VERSION ""

NS_ :

BS_:

BU_: MASTER_BMS SUB_BMS
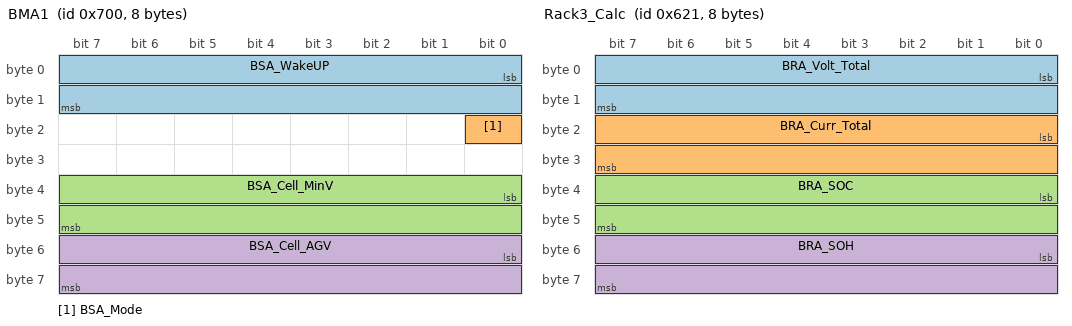
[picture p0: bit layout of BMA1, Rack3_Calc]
BO_ 1792 BMA1: 8 MASTER_BMS SUB_BMS
 SG_ BSA_WakeUP : 0|16@1+ (1.0,0) [0.0|1.0] "flag"  MASTER_BMS SUB_BMS
 SG_ BSA_Mode : 16|1@1+ (1.0,0) [0.0|1.0] "flag"  MASTER_BMS SUB_BMS
 SG_ BSA_Cell_MinV : 32|16@1+ (0.001,0) [2.8|4.5] "V"  MASTER_BMS SUB_BMS
 SG_ BSA_Cell_AGV : 48|16@1- (0.1,0) [-40.0|100.0] "℃"  MASTER_BMS SUB_BMS
BO_ 1569 Rack3_Calc: 8 MASTER_BMS SUB_BMS
 SG_ BRA_Volt_Total : 0|16@1+ (0.1,0) [40.0|120.0] "V"  MASTER_BMS SUB_BMS
 SG_ BRA_Curr_Total : 16|16@1- (0.1,0) [-500.0|500.0] "A"  MASTER_BMS SUB_BMS
 SG_ BRA_SOC : 32|16@1+ (0.1,0) [0.0|120.0] "%"  MASTER_BMS SUB_BMS
 SG_ BRA_SOH : 48|16@1- (0.1,0) [0.0|100.0] "%"  MASTER_BMS SUB_BMS
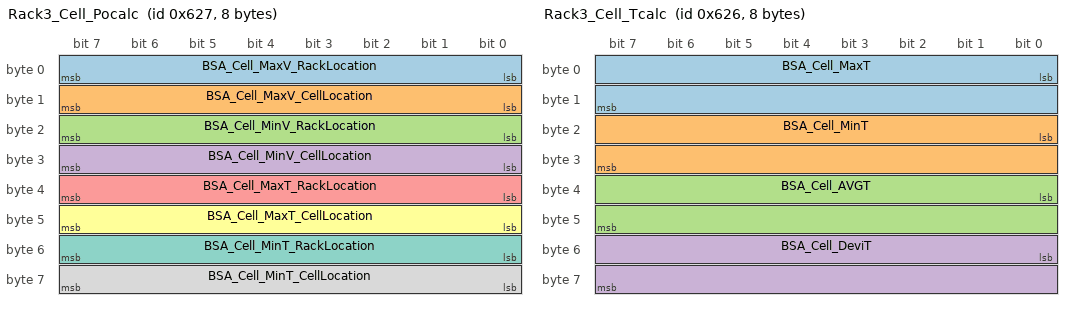
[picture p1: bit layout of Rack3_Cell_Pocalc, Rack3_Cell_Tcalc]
BO_ 1575 Rack3_Cell_Pocalc: 8 MASTER_BMS SUB_BMS
 SG_ BSA_Cell_MaxV_RackLocation : 0|8@1+ (1.0,0) [1.0|4.0] "R"  MASTER_BMS SUB_BMS
 SG_ BSA_Cell_MaxV_CellLocation : 8|8@1+ (1.0,0) [1.0|168.0] "C"  MASTER_BMS SUB_BMS
 SG_ BSA_Cell_MinV_RackLocation : 16|8@1+ (1.0,0) [1.0|4.0] "R"  MASTER_BMS SUB_BMS
 SG_ BSA_Cell_MinV_CellLocation : 24|8@1+ (1.0,0) [1.0|168.0] "C"  MASTER_BMS SUB_BMS
 SG_ BSA_Cell_MaxT_RackLocation : 32|8@1+ (1.0,0) [1.0|4.0] "R"  MASTER_BMS SUB_BMS
 SG_ BSA_Cell_MaxT_CellLocation : 40|8@1+ (1.0,0) [1.0|168.0] "C"  MASTER_BMS SUB_BMS
 SG_ BSA_Cell_MinT_RackLocation : 48|8@1+ (1.0,0) [1.0|4.0] "R"  MASTER_BMS SUB_BMS
 SG_ BSA_Cell_MinT_CellLocation : 56|8@1+ (1.0,0) [1.0|168.0] "C"  MASTER_BMS SUB_BMS
BO_ 1574 Rack3_Cell_Tcalc: 8 MASTER_BMS SUB_BMS
 SG_ BSA_Cell_MaxT : 0|16@1- (0.1,0) [-40.0|100.0] "℃"  MASTER_BMS SUB_BMS
 SG_ BSA_Cell_MinT : 16|16@1- (0.1,0) [-40.0|100.0] "℃"  MASTER_BMS SUB_BMS
 SG_ BSA_Cell_AVGT : 32|16@1- (0.1,0) [-40.0|100.0] "℃"  MASTER_BMS SUB_BMS
 SG_ BSA_Cell_DeviT : 48|16@1+ (0.1,0) [0.0|25.0] "℃"  MASTER_BMS SUB_BMS
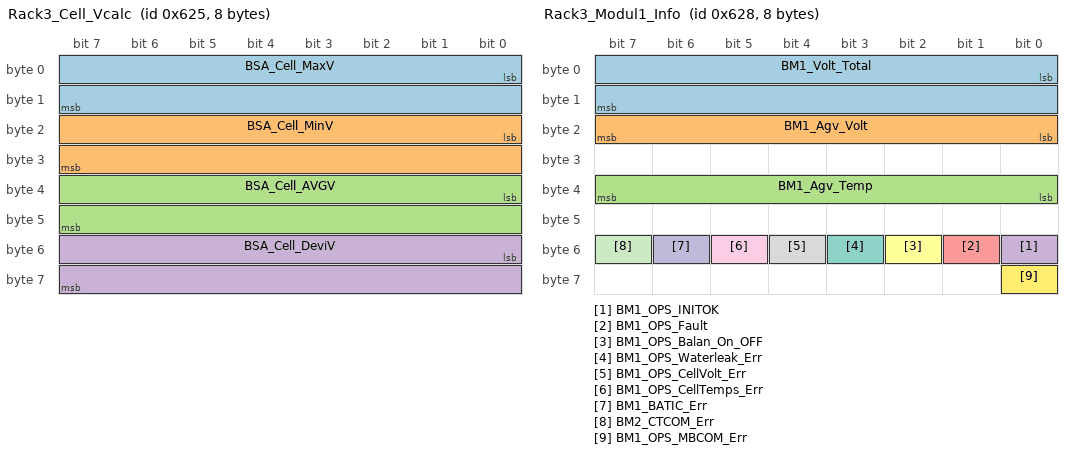
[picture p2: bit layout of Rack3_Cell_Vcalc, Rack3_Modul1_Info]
BO_ 1573 Rack3_Cell_Vcalc: 8 MASTER_BMS SUB_BMS
 SG_ BSA_Cell_MaxV : 0|16@1+ (0.001,0) [2.8|4.5] "V"  MASTER_BMS SUB_BMS
 SG_ BSA_Cell_MinV : 16|16@1+ (0.001,0) [2.8|4.5] "V"  MASTER_BMS SUB_BMS
 SG_ BSA_Cell_AVGV : 32|16@1+ (0.001,0) [2.8|4.5] "V"  MASTER_BMS SUB_BMS
 SG_ BSA_Cell_DeviV : 48|16@1+ (1.0,0) [0.0|500.0] "mV"  MASTER_BMS SUB_BMS
BO_ 1576 Rack3_Modul1_Info: 8 MASTER_BMS SUB_BMS
 SG_ BM1_Volt_Total : 0|16@1+ (0.1,0) [48.0|108.0] "V"  MASTER_BMS SUB_BMS
 SG_ BM1_Agv_Volt : 16|8@1+ (0.001,0) [2.8|4.5] "V"  MASTER_BMS SUB_BMS
 SG_ BM1_Agv_Temp : 32|8@1- (0.1,0) [-40.0|100.0] "℃"  MASTER_BMS SUB_BMS
 SG_ BM1_OPS_INITOK : 48|1@1+ (0.0,0) [0.0|1.0] "flag"  MASTER_BMS SUB_BMS
 SG_ BM1_OPS_Fault : 49|1@1+ (0.0,0) [0.0|1.0] "flag"  MASTER_BMS SUB_BMS
 SG_ BM1_OPS_Balan_On_OFF : 50|1@1+ (0.0,0) [0.0|1.0] "flag"  MASTER_BMS SUB_BMS
 SG_ BM1_OPS_Waterleak_Err : 51|1@1+ (0.0,0) [0.0|1.0] "flag"  MASTER_BMS SUB_BMS
 SG_ BM1_OPS_CellVolt_Err : 52|1@1+ (0.0,0) [0.0|1.0] "flag"  MASTER_BMS SUB_BMS
 SG_ BM1_OPS_CellTemps_Err : 53|1@1+ (0.0,0) [0.0|1.0] "flag"  MASTER_BMS SUB_BMS
 SG_ BM1_BATIC_Err : 54|1@1+ (0.0,0) [0.0|1.0] "flag"  MASTER_BMS SUB_BMS
 SG_ BM2_CTCOM_Err : 55|1@1+ (0.0,0) [0.0|1.0] "flag"  MASTER_BMS SUB_BMS
 SG_ BM1_OPS_MBCOM_Err : 56|1@1+ (0.0,0) [0.0|1.0] "flag"  MASTER_BMS SUB_BMS
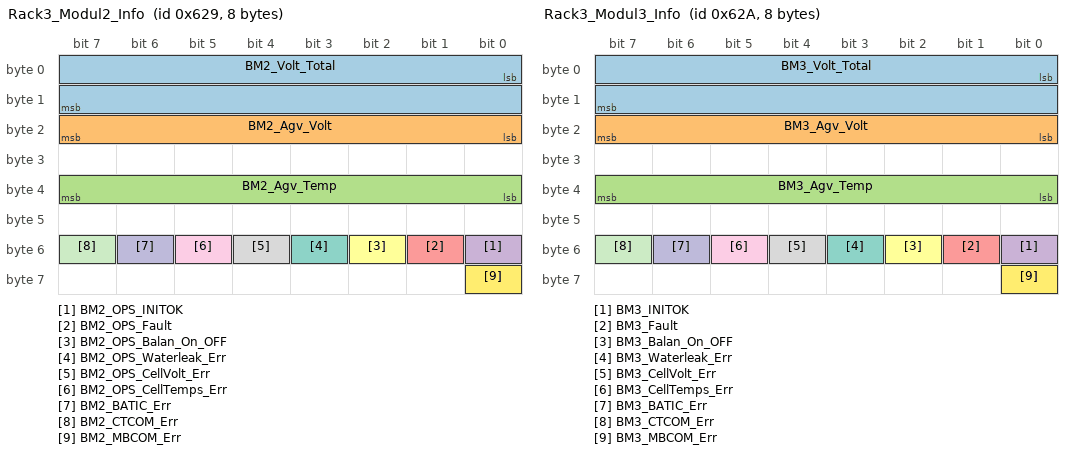
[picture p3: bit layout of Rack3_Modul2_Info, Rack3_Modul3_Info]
BO_ 1577 Rack3_Modul2_Info: 8 MASTER_BMS SUB_BMS
 SG_ BM2_Volt_Total : 0|16@1+ (0.1,0) [48.0|108.0] "V"  MASTER_BMS SUB_BMS
 SG_ BM2_Agv_Volt : 16|8@1+ (0.001,0) [2.8|4.5] "V"  MASTER_BMS SUB_BMS
 SG_ BM2_Agv_Temp : 32|8@1- (0.1,0) [-40.0|100.0] "℃"  MASTER_BMS SUB_BMS
 SG_ BM2_OPS_INITOK : 48|1@1+ (0.0,0) [0.0|1.0] "flag"  MASTER_BMS SUB_BMS
 SG_ BM2_OPS_Fault : 49|1@1+ (0.0,0) [0.0|1.0] "flag"  MASTER_BMS SUB_BMS
 SG_ BM2_OPS_Balan_On_OFF : 50|1@1+ (0.0,0) [0.0|1.0] "flag"  MASTER_BMS SUB_BMS
 SG_ BM2_OPS_Waterleak_Err : 51|1@1+ (0.0,0) [0.0|1.0] "flag"  MASTER_BMS SUB_BMS
 SG_ BM2_OPS_CellVolt_Err : 52|1@1+ (0.0,0) [0.0|1.0] "flag"  MASTER_BMS SUB_BMS
 SG_ BM2_OPS_CellTemps_Err : 53|1@1+ (0.0,0) [0.0|1.0] "flag"  MASTER_BMS SUB_BMS
 SG_ BM2_BATIC_Err : 54|1@1+ (0.0,0) [0.0|1.0] "flag"  MASTER_BMS SUB_BMS
 SG_ BM2_CTCOM_Err : 55|1@1+ (0.0,0) [0.0|1.0] "flag"  MASTER_BMS SUB_BMS
 SG_ BM2_MBCOM_Err : 56|1@1+ (0.0,0) [0.0|1.0] "flag"  MASTER_BMS SUB_BMS
BO_ 1578 Rack3_Modul3_Info: 8 MASTER_BMS SUB_BMS
 SG_ BM3_Volt_Total : 0|16@1+ (0.1,0) [48.0|108.0] "V"  MASTER_BMS SUB_BMS
 SG_ BM3_Agv_Volt : 16|8@1+ (0.001,0) [2.8|4.5] "V"  MASTER_BMS SUB_BMS
 SG_ BM3_Agv_Temp : 32|8@1- (0.1,0) [-40.0|100.0] "℃"  MASTER_BMS SUB_BMS
 SG_ BM3_INITOK : 48|1@1+ (0.0,0) [0.0|1.0] "flag"  MASTER_BMS SUB_BMS
 SG_ BM3_Fault : 49|1@1+ (0.0,0) [0.0|1.0] "flag"  MASTER_BMS SUB_BMS
 SG_ BM3_Balan_On_OFF : 50|1@1+ (0.0,0) [0.0|1.0] "flag"  MASTER_BMS SUB_BMS
 SG_ BM3_Waterleak_Err : 51|1@1+ (0.0,0) [0.0|1.0] "flag"  MASTER_BMS SUB_BMS
 SG_ BM3_CellVolt_Err : 52|1@1+ (0.0,0) [0.0|1.0] "flag"  MASTER_BMS SUB_BMS
 SG_ BM3_CellTemps_Err : 53|1@1+ (0.0,0) [0.0|1.0] "flag"  MASTER_BMS SUB_BMS
 SG_ BM3_BATIC_Err : 54|1@1+ (0.0,0) [0.0|1.0] "flag"  MASTER_BMS SUB_BMS
 SG_ BM3_CTCOM_Err : 55|1@1+ (0.0,0) [0.0|1.0] "flag"  MASTER_BMS SUB_BMS
 SG_ BM3_MBCOM_Err : 56|1@1+ (0.0,0) [0.0|1.0] "flag"  MASTER_BMS SUB_BMS
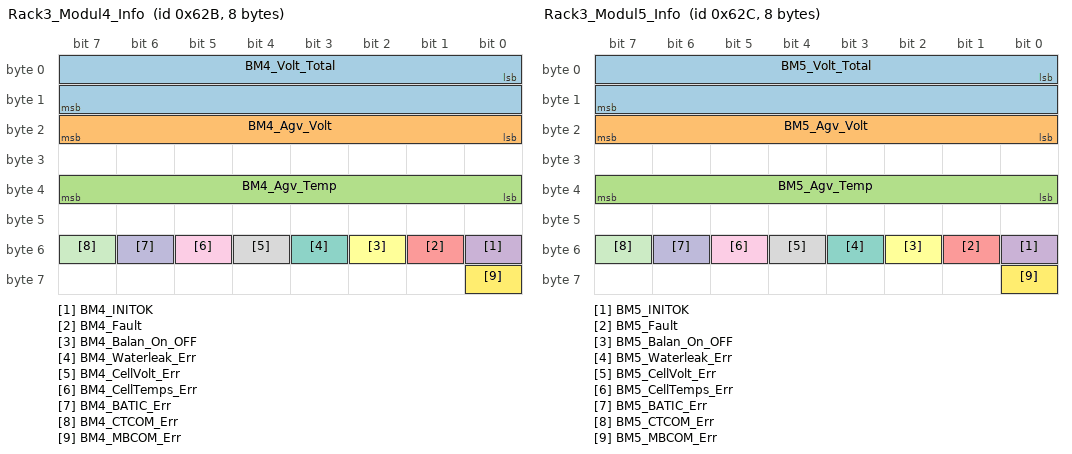
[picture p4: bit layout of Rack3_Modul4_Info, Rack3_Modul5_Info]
BO_ 1579 Rack3_Modul4_Info: 8 MASTER_BMS SUB_BMS
 SG_ BM4_Volt_Total : 0|16@1+ (0.1,0) [48.0|108.0] "V"  MASTER_BMS SUB_BMS
 SG_ BM4_Agv_Volt : 16|8@1+ (0.001,0) [2.8|4.5] "V"  MASTER_BMS SUB_BMS
 SG_ BM4_Agv_Temp : 32|8@1- (0.1,0) [-40.0|100.0] "℃"  MASTER_BMS SUB_BMS
 SG_ BM4_INITOK : 48|1@1+ (0.0,0) [0.0|1.0] "flag"  MASTER_BMS SUB_BMS
 SG_ BM4_Fault : 49|1@1+ (0.0,0) [0.0|1.0] "flag"  MASTER_BMS SUB_BMS
 SG_ BM4_Balan_On_OFF : 50|1@1+ (0.0,0) [0.0|1.0] "flag"  MASTER_BMS SUB_BMS
 SG_ BM4_Waterleak_Err : 51|1@1+ (0.0,0) [0.0|1.0] "flag"  MASTER_BMS SUB_BMS
 SG_ BM4_CellVolt_Err : 52|1@1+ (0.0,0) [0.0|1.0] "flag"  MASTER_BMS SUB_BMS
 SG_ BM4_CellTemps_Err : 53|1@1+ (0.0,0) [0.0|1.0] "flag"  MASTER_BMS SUB_BMS
 SG_ BM4_BATIC_Err : 54|1@1+ (0.0,0) [0.0|1.0] "flag"  MASTER_BMS SUB_BMS
 SG_ BM4_CTCOM_Err : 55|1@1+ (0.0,0) [0.0|1.0] "flag"  MASTER_BMS SUB_BMS
 SG_ BM4_MBCOM_Err : 56|1@1+ (0.0,0) [0.0|1.0] "flag"  MASTER_BMS SUB_BMS
BO_ 1580 Rack3_Modul5_Info: 8 MASTER_BMS SUB_BMS
 SG_ BM5_Volt_Total : 0|16@1+ (0.1,0) [48.0|108.0] "V"  MASTER_BMS SUB_BMS
 SG_ BM5_Agv_Volt : 16|8@1+ (0.001,0) [2.8|4.5] "V"  MASTER_BMS SUB_BMS
 SG_ BM5_Agv_Temp : 32|8@1- (0.1,0) [-40.0|100.0] "℃"  MASTER_BMS SUB_BMS
 SG_ BM5_INITOK : 48|1@1+ (0.0,0) [0.0|1.0] "flag"  MASTER_BMS SUB_BMS
 SG_ BM5_Fault : 49|1@1+ (0.0,0) [0.0|1.0] "flag"  MASTER_BMS SUB_BMS
 SG_ BM5_Balan_On_OFF : 50|1@1+ (0.0,0) [0.0|1.0] "flag"  MASTER_BMS SUB_BMS
 SG_ BM5_Waterleak_Err : 51|1@1+ (0.0,0) [0.0|1.0] "flag"  MASTER_BMS SUB_BMS
 SG_ BM5_CellVolt_Err : 52|1@1+ (0.0,0) [0.0|1.0] "flag"  MASTER_BMS SUB_BMS
 SG_ BM5_CellTemps_Err : 53|1@1+ (0.0,0) [0.0|1.0] "flag"  MASTER_BMS SUB_BMS
 SG_ BM5_BATIC_Err : 54|1@1+ (0.0,0) [0.0|1.0] "flag"  MASTER_BMS SUB_BMS
 SG_ BM5_CTCOM_Err : 55|1@1+ (0.0,0) [0.0|1.0] "flag"  MASTER_BMS SUB_BMS
 SG_ BM5_MBCOM_Err : 56|1@1+ (0.0,0) [0.0|1.0] "flag"  MASTER_BMS SUB_BMS
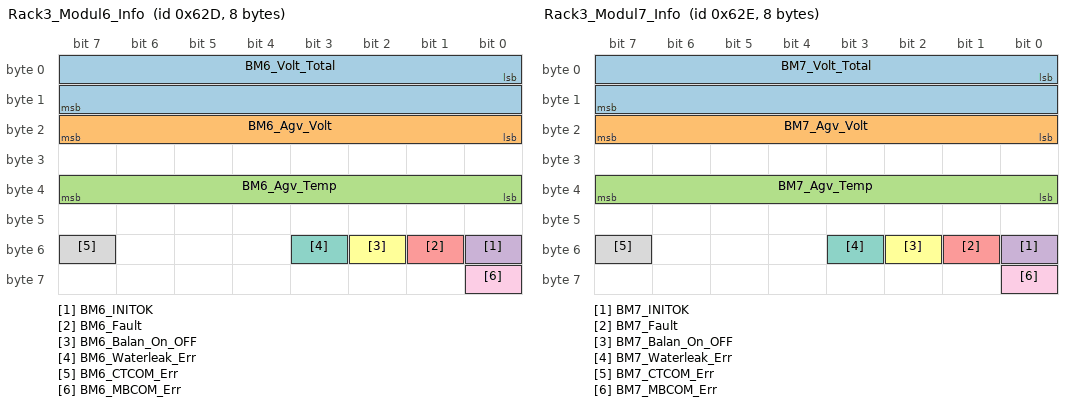
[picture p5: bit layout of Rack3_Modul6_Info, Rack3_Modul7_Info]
BO_ 1581 Rack3_Modul6_Info: 8 MASTER_BMS SUB_BMS
 SG_ BM6_Volt_Total : 0|16@1+ (0.1,0) [48.0|108.0] "V"  MASTER_BMS SUB_BMS
 SG_ BM6_Agv_Volt : 16|8@1+ (0.001,0) [2.8|4.5] "V"  MASTER_BMS SUB_BMS
 SG_ BM6_Agv_Temp : 32|8@1- (0.1,0) [-40.0|100.0] "℃"  MASTER_BMS SUB_BMS
 SG_ BM6_INITOK : 48|1@1+ (0.0,0) [0.0|1.0] "flag"  MASTER_BMS SUB_BMS
 SG_ BM6_Fault : 49|1@1+ (0.0,0) [0.0|1.0] "flag"  MASTER_BMS SUB_BMS
 SG_ BM6_Balan_On_OFF : 50|1@1+ (0.0,0) [0.0|1.0] "flag"  MASTER_BMS SUB_BMS
 SG_ BM6_Waterleak_Err : 51|1@1+ (0.0,0) [0.0|1.0] "flag"  MASTER_BMS SUB_BMS
 SG_ BM6_CTCOM_Err : 55|1@1+ (0.0,0) [0.0|1.0] "flag"  MASTER_BMS SUB_BMS
 SG_ BM6_MBCOM_Err : 56|1@1+ (0.0,0) [0.0|1.0] "flag"  MASTER_BMS SUB_BMS
BO_ 1582 Rack3_Modul7_Info: 8 MASTER_BMS SUB_BMS
 SG_ BM7_Volt_Total : 0|16@1+ (0.1,0) [48.0|108.0] "V"  MASTER_BMS SUB_BMS
 SG_ BM7_Agv_Volt : 16|8@1+ (0.001,0) [2.8|4.5] "V"  MASTER_BMS SUB_BMS
 SG_ BM7_Agv_Temp : 32|8@1- (0.1,0) [-40.0|100.0] "℃"  MASTER_BMS SUB_BMS
 SG_ BM7_INITOK : 48|1@1+ (0.0,0) [0.0|1.0] "flag"  MASTER_BMS SUB_BMS
 SG_ BM7_Fault : 49|1@1+ (0.0,0) [0.0|1.0] "flag"  MASTER_BMS SUB_BMS
 SG_ BM7_Balan_On_OFF : 50|1@1+ (0.0,0) [0.0|1.0] "flag"  MASTER_BMS SUB_BMS
 SG_ BM7_Waterleak_Err : 51|1@1+ (0.0,0) [0.0|1.0] "flag"  MASTER_BMS SUB_BMS
 SG_ BM7_CTCOM_Err : 55|1@1+ (0.0,0) [0.0|1.0] "flag"  MASTER_BMS SUB_BMS
 SG_ BM7_MBCOM_Err : 56|1@1+ (0.0,0) [0.0|1.0] "flag"  MASTER_BMS SUB_BMS
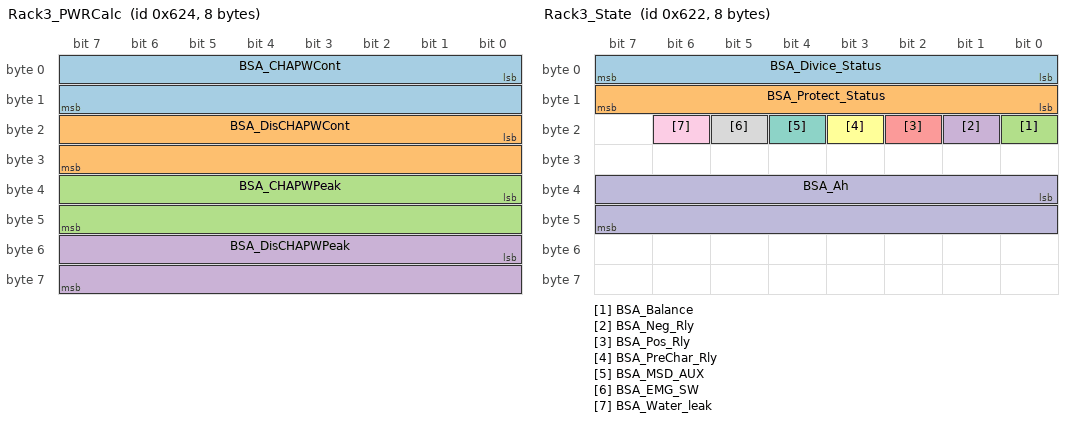
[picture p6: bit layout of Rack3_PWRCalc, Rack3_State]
BO_ 1572 Rack3_PWRCalc: 8 MASTER_BMS SUB_BMS
 SG_ BSA_CHAPWCont : 0|16@1+ (0.1,0) [0.0|43.0] "kw"  MASTER_BMS SUB_BMS
 SG_ BSA_DisCHAPWCont : 16|16@1+ (0.1,0) [0.0|100.0] "kw"  MASTER_BMS SUB_BMS
 SG_ BSA_CHAPWPeak : 32|16@1+ (0.1,0) [0.0|60.0] "kW"  MASTER_BMS SUB_BMS
 SG_ BSA_DisCHAPWPeak : 48|16@1+ (0.1,0) [0.0|200.0] "kW"  MASTER_BMS SUB_BMS
BO_ 1571 Rack3_ProtectState: 8 MASTER_BMS SUB_BMS
 SG_ BSA_Wn_Dischager_OC : 0|1@1+ (1.0,0) [0.0|1.0] "flag"  MASTER_BMS SUB_BMS
 SG_ BSA_Wn_Chager_OC : 1|1@1+ (1.0,0) [0.0|1.0] "flag"  MASTER_BMS SUB_BMS
 SG_ BSA_Wn_SOC_OV : 2|1@1+ (1.0,0) [0.0|1.0] "flag"  MASTER_BMS SUB_BMS
 SG_ BSA_Wn_SOC_Un : 3|1@1+ (1.0,0) [0.0|1.0] "flag"  MASTER_BMS SUB_BMS
 SG_ BSA_Wn_OV : 4|1@1+ (1.0,0) [0.0|1.0] "flag"  MASTER_BMS SUB_BMS
 SG_ BSA_Wn_UV : 5|1@1+ (1.0,0) [0.0|1.0] "flag"  MASTER_BMS SUB_BMS
 SG_ BSA_Wn_Cell_OV : 6|1@1+ (1.0,0) [0.0|1.0] "flag"  MASTER_BMS SUB_BMS
 SG_ BSA_Wn_Cell_UV : 7|1@1+ (1.0,0) [0.0|1.0] "flag"  MASTER_BMS SUB_BMS
 SG_ BSA_Wn_Cell_UnbalV : 8|1@1+ (1.0,0) [0.0|1.0] "flag"  MASTER_BMS SUB_BMS
 SG_ BSA_Wn_DisCharger_Cell_OT : 9|1@1+ (1.0,0) [0.0|1.0] "flag"  MASTER_BMS SUB_BMS
 SG_ BSA_Wn_Charger_Cell_OT : 10|1@1+ (1.0,0) [0.0|1.0] "flag"  MASTER_BMS SUB_BMS
 SG_ BSA_Wn_DisCharger_Cell_UT : 11|1@1+ (1.0,0) [0.0|1.0] "flag"  MASTER_BMS SUB_BMS
 SG_ BSA_Wn_Charger_Cell_UT : 12|1@1+ (1.0,0) [0.0|1.0] "flag"  MASTER_BMS SUB_BMS
 SG_ BSA_Wn_Cell_UnbalT : 13|1@1+ (1.0,0) [0.0|1.0] "flag"  MASTER_BMS SUB_BMS
 SG_ BSA_Wn_Discharger_UnbaPWR : 14|1@1+ (1.0,0) [0.0|1.0] "flag"  MASTER_BMS SUB_BMS
 SG_ BSA_Wn_Charger_UnbaPWR : 15|1@1+ (1.0,0) [0.0|1.0] "flag"  MASTER_BMS SUB_BMS
 SG_ BSA_FLT_Dischager_OC : 16|1@1+ (1.0,0) [0.0|1.0] "flag"  MASTER_BMS SUB_BMS
 SG_ BSA_FLT_Chager_OC : 17|1@1+ (1.0,0) [0.0|1.0] "flag"  MASTER_BMS SUB_BMS
 SG_ BSA_FLT_SOC_OV : 18|1@1+ (1.0,0) [0.0|1.0] "flag"  MASTER_BMS SUB_BMS
 SG_ BSA_FLT_SOC_Un : 19|1@1+ (1.0,0) [0.0|1.0] "flag"  MASTER_BMS SUB_BMS
 SG_ BSA_FLT_OV : 20|1@1+ (1.0,0) [0.0|1.0] "flag"  MASTER_BMS SUB_BMS
 SG_ BSA_FLT_UV : 21|1@1+ (1.0,0) [0.0|1.0] "flag"  MASTER_BMS SUB_BMS
 SG_ BSA_FLT_Cell_OV : 22|1@1+ (1.0,0) [0.0|1.0] "flag"  MASTER_BMS SUB_BMS
 SG_ BSA_FLT_Cell_UV : 23|1@1+ (1.0,0) [0.0|1.0] "flag"  MASTER_BMS SUB_BMS
 SG_ BSA_FLT_Cell_UnbalV : 24|1@1+ (1.0,0) [0.0|1.0] "flag"  MASTER_BMS SUB_BMS
 SG_ BSA_FLT_DisCharger_Cell_OT : 25|1@1+ (1.0,0) [0.0|1.0] "flag"  MASTER_BMS SUB_BMS
 SG_ BSA_FLT_Charger_Cell_OT : 26|1@1+ (1.0,0) [0.0|1.0] "flag"  MASTER_BMS SUB_BMS
 SG_ BSA_FLT_DisCharger_Cell_UT : 27|1@1+ (1.0,0) [0.0|1.0] "flag"  MASTER_BMS SUB_BMS
 SG_ BSA_FLT_Charger_Cell_UT : 28|1@1+ (1.0,0) [0.0|1.0] "flag"  MASTER_BMS SUB_BMS
 SG_ BSA_FLT_Cell_UnbalT : 29|1@1+ (1.0,0) [0.0|1.0] "flag"  MASTER_BMS SUB_BMS
 SG_ BSA_FLT_Discharger_UnbaPWR : 30|1@1+ (1.0,0) [0.0|1.0] "flag"  MASTER_BMS SUB_BMS
 SG_ BSA_FLT_Charger_UnbaPWR : 31|1@1+ (1.0,0) [0.0|1.0] "flag"  MASTER_BMS SUB_BMS
 SG_ BSA_Prtct_Dischager_OC : 32|1@1+ (1.0,0) [0.0|1.0] "flag"  MASTER_BMS SUB_BMS
 SG_ BSA_Prtct_Chager_OC : 33|1@1+ (1.0,0) [0.0|1.0] "flag"  MASTER_BMS SUB_BMS
 SG_ BSA_Prtct_SOC_OV : 34|1@1+ (1.0,0) [0.0|1.0] "flag"  MASTER_BMS SUB_BMS
 SG_ BSA_Prtct_SOC_Un : 35|1@1+ (1.0,0) [0.0|1.0] "flag"  MASTER_BMS SUB_BMS
 SG_ BSA_Prtct_OV : 36|1@1+ (1.0,0) [0.0|1.0] "flag"  MASTER_BMS SUB_BMS
 SG_ BSA_Prtct_UV : 37|1@1+ (1.0,0) [0.0|1.0] "flag"  MASTER_BMS SUB_BMS
 SG_ BSA_Prtct_Cell_OV : 38|1@1+ (1.0,0) [0.0|1.0] "flag"  MASTER_BMS SUB_BMS
 SG_ BSA_Prtct_Cell_UV : 39|1@1+ (1.0,0) [0.0|1.0] "flag"  MASTER_BMS SUB_BMS
 SG_ BSA_Prtct_Cell_UnbalV : 40|1@1+ (1.0,0) [0.0|1.0] "flag"  MASTER_BMS SUB_BMS
 SG_ BSA_Prtct_DisCharger_Cell_OT : 41|1@1+ (1.0,0) [0.0|1.0] "flag"  MASTER_BMS SUB_BMS
 SG_ BSA_Prtct_Charger_Cell_OT : 42|1@1+ (1.0,0) [0.0|1.0] "flag"  MASTER_BMS SUB_BMS
 SG_ BSA_Prtct_DisCharger_Cell_UT : 43|1@1+ (1.0,0) [0.0|1.0] "flag"  MASTER_BMS SUB_BMS
 SG_ BSA_Prtct_Charger_Cell_UT : 44|1@1+ (1.0,0) [0.0|1.0] "flag"  MASTER_BMS SUB_BMS
 SG_ BSA_Prtct_Cell_UnbalT : 45|1@1+ (1.0,0) [0.0|1.0] "flag"  MASTER_BMS SUB_BMS
 SG_ BSA_Prtct_Discharger_UnbaPWR : 46|1@1+ (1.0,0) [0.0|1.0] "flag"  MASTER_BMS SUB_BMS
 SG_ BSA_Prtct_Charger_UnbaPWR : 47|1@1+ (1.0,0) [0.0|1.0] "flag"  MASTER_BMS SUB_BMS
 SG_ BSA_Prtct_Rly_Err : 48|1@1+ (1.0,0) [0.0|1.0] "flag"  MASTER_BMS SUB_BMS
 SG_ BSA_Prtct_IN_COM_Err : 49|1@1+ (1.0,0) [0.0|1.0] "flag"  MASTER_BMS SUB_BMS
 SG_ BSA_Prtct_EX_COM_Err : 50|1@1+ (1.0,0) [0.0|1.0] "flag"  MASTER_BMS SUB_BMS
 SG_ BSA_Prtct_CT_COM_Err : 51|1@1+ (1.0,0) [0.0|1.0] "flag"  MASTER_BMS SUB_BMS
 SG_ BSA_Prtct_Water_Leak_Err : 52|1@1+ (1.0,0) [0.0|1.0] "flag"  MASTER_BMS SUB_BMS
 SG_ BSA_Prtct_EMS_SW_Err : 53|1@1+ (1.0,0) [0.0|1.0] "flag"  MASTER_BMS SUB_BMS
 SG_ Not_Used : 54|1@1+ (1.0,0) [0.0|1.0] "flag"  MASTER_BMS SUB_BMS
 SG_ Not_Used : 55|1@1+ (1.0,0) [0.0|1.0] "flag"  MASTER_BMS SUB_BMS
 SG_ Not_Used : 56|1@1+ (1.0,0) [0.0|1.0] "flag"  MASTER_BMS SUB_BMS
 SG_ Not_Used : 57|1@1+ (1.0,0) [0.0|1.0] "flag"  MASTER_BMS SUB_BMS
 SG_ Not_Used : 58|1@1+ (1.0,0) [0.0|1.0] "flag"  MASTER_BMS SUB_BMS
 SG_ Not_Used : 59|1@1+ (1.0,0) [0.0|1.0] "flag"  MASTER_BMS SUB_BMS
 SG_ Not_Used : 60|1@1+ (1.0,0) [0.0|1.0] "flag"  MASTER_BMS SUB_BMS
 SG_ Not_Used : 61|1@1+ (1.0,0) [0.0|1.0] "flag"  MASTER_BMS SUB_BMS
 SG_ Not_Used : 62|1@1+ (1.0,0) [0.0|1.0] "flag"  MASTER_BMS SUB_BMS
 SG_ Not_Used : 63|1@1+ (1.0,0) [0.0|1.0] "flag"  MASTER_BMS SUB_BMS
BO_ 1570 Rack3_State: 8 MASTER_BMS SUB_BMS
 SG_ BSA_Divice_Status : 0|8@1+ (1.0,0) [0.0|4.0] "State"  MASTER_BMS SUB_BMS
 SG_ BSA_Protect_Status : 8|8@1+ (1.0,0) [0.0|4.0] "State"  MASTER_BMS SUB_BMS
 SG_ BSA_Balance : 16|1@1+ (1.0,0) [0.0|1.0] "flag"  MASTER_BMS SUB_BMS
 SG_ BSA_Neg_Rly : 17|1@1+ (1.0,0) [0.0|1.0] "flag"  MASTER_BMS SUB_BMS
 SG_ BSA_Pos_Rly : 18|1@1+ (1.0,0) [0.0|1.0] "flag"  MASTER_BMS SUB_BMS
 SG_ BSA_PreChar_Rly : 19|1@1+ (1.0,0) [0.0|1.0] "flag"  MASTER_BMS SUB_BMS
 SG_ BSA_MSD_AUX : 20|1@1+ (1.0,0) [0.0|1.0] "flag"  MASTER_BMS SUB_BMS
 SG_ BSA_EMG_SW : 21|1@1+ (1.0,0) [0.0|1.0] "flag"  MASTER_BMS SUB_BMS
 SG_ BSA_Water_leak : 22|1@1+ (1.0,0) [0.0|1.0] "flag"  MASTER_BMS SUB_BMS
 SG_ Not Used : 23|1@1+ (1.0,0) [0.0|1.0] "flag"  MASTER_BMS SUB_BMS
 SG_ Not Used : 24|1@1+ (1.0,0) [0.0|1.0] "flag"  MASTER_BMS SUB_BMS
 SG_ Not Used : 25|1@1+ (1.0,0) [0.0|1.0] "flag"  MASTER_BMS SUB_BMS
 SG_ Not Used : 26|1@1+ (1.0,0) [0.0|1.0] "flag"  MASTER_BMS SUB_BMS
 SG_ Not Used : 27|1@1+ (1.0,0) [0.0|1.0] "flag"  MASTER_BMS SUB_BMS
 SG_ Not Used : 28|1@1+ (1.0,0) [0.0|1.0] "flag"  MASTER_BMS SUB_BMS
 SG_ Not Used : 29|1@1+ (1.0,0) [0.0|1.0] "flag"  MASTER_BMS SUB_BMS
 SG_ Not Used : 30|1@1+ (1.0,0) [0.0|1.0] "flag"  MASTER_BMS SUB_BMS
 SG_ Not Used : 31|1@1+ (1.0,0) [0.0|1.0] "flag"  MASTER_BMS SUB_BMS
 SG_ BSA_Ah : 32|16@1- (1.0,0) [-100.0|-100.0] "Ah"  MASTER_BMS SUB_BMS
 SG_ Not Used : 48|16@1+ (1.0,0) [0.0|0.0] "NOT"  MASTER_BMS SUB_BMS
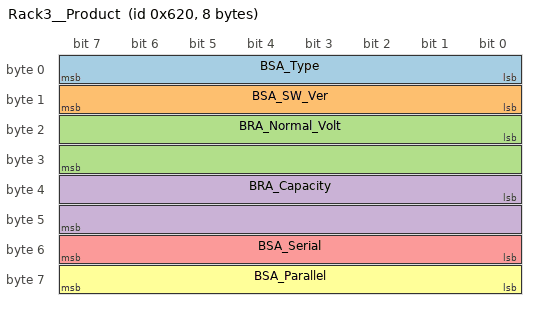
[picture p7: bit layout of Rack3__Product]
BO_ 1568 Rack3__Product: 8 MASTER_BMS SUB_BMS
 SG_ BSA_Type : 0|8@1+ (1.0,0) [0.0|10.0] "Ty"  MASTER_BMS SUB_BMS
 SG_ BSA_SW_Ver : 8|8@1- (1.0,0) [1.0|10.0] "VER"  MASTER_BMS SUB_BMS
 SG_ BRA_Normal_Volt : 16|16@1+ (0.1,0) [0.0|100.0] "V"  MASTER_BMS SUB_BMS
 SG_ BRA_Capacity : 32|16@1+ (0.1,0) [30.0|60.0] "Ah"  MASTER_BMS SUB_BMS
 SG_ BSA_Serial : 48|8@1- (1.0,0) [0.0|200.0] "S"  MASTER_BMS SUB_BMS
 SG_ BSA_Parallel : 56|8@1+ (1.0,0) [0.0|10.0] "P"  MASTER_BMS SUB_BMS
